# ESP32-H2 register map
Vendor: ESPRESSIF SYSTEMS (SHANGHAI) CO., LTD.; Series: ESP32 H-Series; File version: 12
CPU: RV32IMAC r0p0, little endian, no MPU, no FPU, 0 interrupt priority bits
Address unit: 32 bits
Registers are 32-bit, read-write, reset 0x0 unless marked. A register's access mark holds for its fields unless they carry their own. Offsets are from the block's base; [hi:lo] are bit positions; {n}, {i} and the like mark numbered series.

## ECC — ECC (ECC Hardware Accelerator)
Base 0x6008B000
0x0C MULT_INT_RAW ro — ECC interrupt raw register, valid in level.
  [0] CALC_DONE_INT_RAW — The raw interrupt status bit for the ecc_calc_done_int interrupt
0x10 MULT_INT_ST ro — ECC interrupt status register.
  [0] CALC_DONE_INT_ST — The masked interrupt status bit for the ecc_calc_done_int interrupt
0x14 MULT_INT_ENA — ECC interrupt enable register.
  [0] CALC_DONE_INT_ENA — The interrupt enable bit for the ecc_calc_done_int interrupt
0x18 MULT_INT_CLR wo — ECC interrupt clear register.
  [0] CALC_DONE_INT_CLR — Set this bit to clear the ecc_calc_done_int interrupt
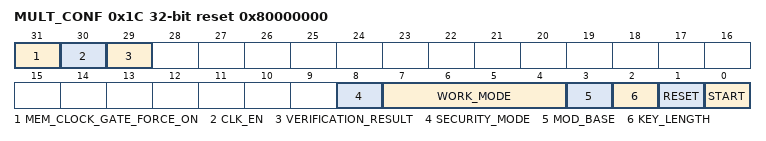
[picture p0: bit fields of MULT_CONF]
0x1C MULT_CONF access per field reset 0x80000000 — ECC configure register
  [31] MEM_CLOCK_GATE_FORCE_ON rw — ECC memory clock gate force on register
  [30] CLK_EN rw — Write 1 to force on register clock gate.
  [29] VERIFICATION_RESULT ro — The verification result bit of ECC Accelerator, only valid when calculation is done.
  [8] SECURITY_MODE rw — Reserved
  [7:4] WORK_MODE rw — The work mode bits of ECC Accelerator. 0: Point Mult Mode. 1: Reserved. 2: Point verification mode. 3: Point Verif+mult mode. 4: Jacobian Point Mult Mode. 5: Point Add Mode. 6: Jacobian Point Verification Mode. 7: Point Verif + Jacobian Mult Mode. 8: mod addition. 9. mod substraction. 10: mod multiplication. 11: mod division.
  [3] MOD_BASE rw — The mod base of mod operation, only valid in work_mode 8-11. 0: n(order of curve). 1: p(mod base of curve)
  [2] KEY_LENGTH rw — The key length mode bit of ECC Accelerator. 0: P-192. 1: P-256.
  [1] RESET wo — Write 1 to reset ECC Accelerator.
  [0] START rw — Write 1 to start caculation of ECC Accelerator. This bit will be self-cleared after the caculatrion is done.
0xFC MULT_DATE reset 0x2207180 — Version control register
  [27:0] DATE — ECC mult version control register
{0x100+i} K_MEM[{i}] (i=0..31) 8-bit access not given — The memory that stores k.
{0x120+i} PX_MEM[{i}] (i=0..31) 8-bit access not given — The memory that stores Px.
{0x140+i} PY_MEM[{i}] (i=0..31) 8-bit access not given — The memory that stores Py.

## HMAC — HMAC (Hash-based Message Authentication Code) Accelerator
Base 0x6008D000
0x40 SET_START wo — Process control register 0.
  [0] SET_START — Start hmac operation.
0x44 SET_PARA_PURPOSE wo — Configure purpose.
  [3:0] PURPOSE_SET — Set hmac parameter purpose.
0x48 SET_PARA_KEY wo — Configure key.
  [2:0] KEY_SET — Set hmac parameter key.
0x4C SET_PARA_FINISH wo — Finish initial configuration.
  [0] SET_PARA_END — Finish hmac configuration.
0x50 SET_MESSAGE_ONE wo — Process control register 1.
  [0] SET_TEXT_ONE — Call SHA to calculate one message block.
0x54 SET_MESSAGE_ING wo — Process control register 2.
  [0] SET_TEXT_ING — Continue typical hmac.
0x58 SET_MESSAGE_END wo — Process control register 3.
  [0] SET_TEXT_END — Start hardware padding.
0x5C SET_RESULT_FINISH wo — Process control register 4.
  [0] SET_RESULT_END — After read result from upstream, then let hmac back to idle.
0x60 SET_INVALIDATE_JTAG wo — Invalidate register 0.
  [0] SET_INVALIDATE_JTAG — Clear result from hmac downstream JTAG.
0x64 SET_INVALIDATE_DS wo — Invalidate register 1.
  [0] SET_INVALIDATE_DS — Clear result from hmac downstream DS.
0x68 QUERY_ERROR ro — Error register.
  [0] QUERY_CHECK — Hmac configuration state. 0: key are agree with purpose. 1: error
0x6C QUERY_BUSY ro — Busy register.
  [0] BUSY_STATE — Hmac state. 1'b0: idle. 1'b1: busy
{0x80+i} WR_MESSAGE_MEM[{i}] (i=0..63) 8-bit access not given — Message block memory.
{0xC0+i} RD_RESULT_MEM[{i}] (i=0..31) 8-bit access not given — Result from upstream.
0xF0 SET_MESSAGE_PAD wo — Process control register 5.
  [0] SET_TEXT_PAD — Start software padding.
0xF4 ONE_BLOCK wo — Process control register 6.
  [0] SET_ONE_BLOCK — Don't have to do padding.
0xF8 SOFT_JTAG_CTRL wo — Jtag register 0.
  [0] SOFT_JTAG_CTRL — Turn on JTAG verification.
0xFC WR_JTAG wo — Jtag register 1.
  [31:0] WR_JTAG — 32-bit of key to be compared.
0x1FC DATE reset 0x20200618
  [29:0] DATE — Hmac date information/ hmac version information.
